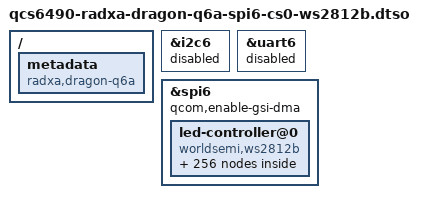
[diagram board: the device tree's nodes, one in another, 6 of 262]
// SPDX-License-Identifier: BSD-3-Clause
/*
 * Copyright (c) 2025 Radxa Computer (Shenzhen) Co., Ltd.
 */

/dts-v1/;
/plugin/;

#include <dt-bindings/leds/common.h>

/ {
    metadata {
        title = "Enable WS2812B on SPI6 over CS0";
        compatible = "radxa,dragon-q6a", "radxa,cm-q64-rpi-cm5-io";
        category = "misc";
        exclusive = "spi6", "uart6", "i2c6", "gpio24", "gpio25", "gpio26", "gpio27";
        description = "Enable WS2812B on SPI6 over CS0.
On Radxa Dragon Q6A and
Radxa CM-Q64 Raspberry Pi Compute Module 5 IO Board,
this is pin 3(miso), 5(mosi), 16(sclk), 18(cs0).";
    };
};

&i2c6 {
	status = "disabled";
};

&uart6 {
	status = "disabled";
};

&spi6 {
	qcom,enable-gsi-dma;
	status = "okay";
	
	led-controller@0 {
		compatible = "worldsemi,ws2812b";
		reg = <0>;
		#address-cells = <1>;
		#size-cells = <0>;
		spi-max-frequency = <2850000>;

		multi-led@0 {
			reg = <0>;
			color-index = <LED_COLOR_ID_RED LED_COLOR_ID_GREEN LED_COLOR_ID_BLUE>;
			color = <LED_COLOR_ID_RGB>;
			function = LED_FUNCTION_STATUS;
			function-enumerator = <0>;
		};

		multi-led@1 {
			reg = <1>;
			color = <LED_COLOR_ID_RGB>;
			function = LED_FUNCTION_STATUS;
			function-enumerator = <1>;
		};

		multi-led@2 {
			reg = <2>;
			color = <LED_COLOR_ID_RGB>;
			function = LED_FUNCTION_STATUS;
			function-enumerator = <2>;
		};

		multi-led@3 {
			reg = <3>;
			color = <LED_COLOR_ID_RGB>;
			function = LED_FUNCTION_STATUS;
			function-enumerator = <3>;
		};

		multi-led@4 {
			reg = <4>;
			color = <LED_COLOR_ID_RGB>;
			function = LED_FUNCTION_STATUS;
			function-enumerator = <4>;
		};

		multi-led@5 {
			reg = <5>;
			color = <LED_COLOR_ID_RGB>;
			function = LED_FUNCTION_STATUS;
			function-enumerator = <5>;
		};

		multi-led@6 {
			reg = <6>;
			color = <LED_COLOR_ID_RGB>;
			function = LED_FUNCTION_STATUS;
			function-enumerator = <6>;
		};

		multi-led@7 {
			reg = <7>;
			color = <LED_COLOR_ID_RGB>;
			function = LED_FUNCTION_STATUS;
			function-enumerator = <7>;
		};

		multi-led@8 {
			reg = <8>;
			color = <LED_COLOR_ID_RGB>;
			function = LED_FUNCTION_STATUS;
			function-enumerator = <8>;
		};

		multi-led@9 {
			reg = <9>;
			color = <LED_COLOR_ID_RGB>;
			function = LED_FUNCTION_STATUS;
			function-enumerator = <9>;
		};

		multi-led@10 {
			reg = <10>;
			color = <LED_COLOR_ID_RGB>;
			function = LED_FUNCTION_STATUS;
			function-enumerator = <10>;
		};

		multi-led@11 {
			reg = <11>;
			color = <LED_COLOR_ID_RGB>;
			function = LED_FUNCTION_STATUS;
			function-enumerator = <11>;
		};

		multi-led@12 {
			reg = <12>;
			color = <LED_COLOR_ID_RGB>;
			function = LED_FUNCTION_STATUS;
			function-enumerator = <12>;
		};

		multi-led@13 {
			reg = <13>;
			color = <LED_COLOR_ID_RGB>;
			function = LED_FUNCTION_STATUS;
			function-enumerator = <13>;
		};

		multi-led@14 {
			reg = <14>;
			color = <LED_COLOR_ID_RGB>;
			function = LED_FUNCTION_STATUS;
			function-enumerator = <14>;
		};

		multi-led@15 {
			reg = <15>;
			color = <LED_COLOR_ID_RGB>;
			function = LED_FUNCTION_STATUS;
			function-enumerator = <15>;
		};

		multi-led@16 {
			reg = <16>;
			color = <LED_COLOR_ID_RGB>;
			function = LED_FUNCTION_STATUS;
			function-enumerator = <16>;
		};

		multi-led@17 {
			reg = <17>;
			color = <LED_COLOR_ID_RGB>;
			function = LED_FUNCTION_STATUS;
			function-enumerator = <17>;
		};

		multi-led@18 {
			reg = <18>;
			color = <LED_COLOR_ID_RGB>;
			function = LED_FUNCTION_STATUS;
			function-enumerator = <18>;
		};

		multi-led@19 {
			reg = <19>;
			color = <LED_COLOR_ID_RGB>;
			function = LED_FUNCTION_STATUS;
			function-enumerator = <19>;
		};

		multi-led@20 {
			reg = <20>;
			color = <LED_COLOR_ID_RGB>;
			function = LED_FUNCTION_STATUS;
			function-enumerator = <20>;
		};

		multi-led@21 {
			reg = <21>;
			color = <LED_COLOR_ID_RGB>;
			function = LED_FUNCTION_STATUS;
			function-enumerator = <21>;
		};

		multi-led@22 {
			reg = <22>;
			color = <LED_COLOR_ID_RGB>;
			function = LED_FUNCTION_STATUS;
			function-enumerator = <22>;
		};

		multi-led@23 {
			reg = <23>;
			color = <LED_COLOR_ID_RGB>;
			function = LED_FUNCTION_STATUS;
			function-enumerator = <23>;
		};

		multi-led@24 {
			reg = <24>;
			color = <LED_COLOR_ID_RGB>;
			function = LED_FUNCTION_STATUS;
			function-enumerator = <24>;
		};

		multi-led@25 {
			reg = <25>;
			color = <LED_COLOR_ID_RGB>;
			function = LED_FUNCTION_STATUS;
			function-enumerator = <25>;
		};

		multi-led@26 {
			reg = <26>;
			color = <LED_COLOR_ID_RGB>;
			function = LED_FUNCTION_STATUS;
			function-enumerator = <26>;
		};

		multi-led@27 {
			reg = <27>;
			color = <LED_COLOR_ID_RGB>;
			function = LED_FUNCTION_STATUS;
			function-enumerator = <27>;
		};

		multi-led@28 {
			reg = <28>;
			color = <LED_COLOR_ID_RGB>;
			function = LED_FUNCTION_STATUS;
			function-enumerator = <28>;
		};

		multi-led@29 {
			reg = <29>;
			color = <LED_COLOR_ID_RGB>;
			function = LED_FUNCTION_STATUS;
			function-enumerator = <29>;
		};

		multi-led@30 {
			reg = <30>;
			color = <LED_COLOR_ID_RGB>;
			function = LED_FUNCTION_STATUS;
			function-enumerator = <30>;
		};

		multi-led@31 {
			reg = <31>;
			color = <LED_COLOR_ID_RGB>;
			function = LED_FUNCTION_STATUS;
			function-enumerator = <31>;
		};

		multi-led@32 {
			reg = <32>;
			color = <LED_COLOR_ID_RGB>;
			function = LED_FUNCTION_STATUS;
			function-enumerator = <32>;
		};

		multi-led@33 {
			reg = <33>;
			color = <LED_COLOR_ID_RGB>;
			function = LED_FUNCTION_STATUS;
			function-enumerator = <33>;
		};

		multi-led@34 {
			reg = <34>;
			color = <LED_COLOR_ID_RGB>;
			function = LED_FUNCTION_STATUS;
			function-enumerator = <34>;
		};

		multi-led@35 {
			reg = <35>;
			color = <LED_COLOR_ID_RGB>;
			function = LED_FUNCTION_STATUS;
			function-enumerator = <35>;
		};

		multi-led@36 {
			reg = <36>;
			color = <LED_COLOR_ID_RGB>;
			function = LED_FUNCTION_STATUS;
			function-enumerator = <36>;
		};

		multi-led@37 {
			reg = <37>;
			color = <LED_COLOR_ID_RGB>;
			function = LED_FUNCTION_STATUS;
			function-enumerator = <37>;
		};

		multi-led@38 {
			reg = <38>;
			color = <LED_COLOR_ID_RGB>;
			function = LED_FUNCTION_STATUS;
			function-enumerator = <38>;
		};

		multi-led@39 {
			reg = <39>;
			color = <LED_COLOR_ID_RGB>;
			function = LED_FUNCTION_STATUS;
			function-enumerator = <39>;
		};

		multi-led@40 {
			reg = <40>;
			color = <LED_COLOR_ID_RGB>;
			function = LED_FUNCTION_STATUS;
			function-enumerator = <40>;
		};

		multi-led@41 {
			reg = <41>;
			color = <LED_COLOR_ID_RGB>;
			function = LED_FUNCTION_STATUS;
			function-enumerator = <41>;
		};

		multi-led@42 {
			reg = <42>;
			color = <LED_COLOR_ID_RGB>;
			function = LED_FUNCTION_STATUS;
			function-enumerator = <42>;
		};

		multi-led@43 {
			reg = <43>;
			color = <LED_COLOR_ID_RGB>;
			function = LED_FUNCTION_STATUS;
			function-enumerator = <43>;
		};

		multi-led@44 {
			reg = <44>;
			color = <LED_COLOR_ID_RGB>;
			function = LED_FUNCTION_STATUS;
			function-enumerator = <44>;
		};

		multi-led@45 {
			reg = <45>;
			color = <LED_COLOR_ID_RGB>;
			function = LED_FUNCTION_STATUS;
			function-enumerator = <45>;
		};

		multi-led@46 {
			reg = <46>;
			color = <LED_COLOR_ID_RGB>;
			function = LED_FUNCTION_STATUS;
			function-enumerator = <46>;
		};

		multi-led@47 {
			reg = <47>;
			color = <LED_COLOR_ID_RGB>;
			function = LED_FUNCTION_STATUS;
			function-enumerator = <47>;
		};

		multi-led@48 {
			reg = <48>;
			color = <LED_COLOR_ID_RGB>;
			function = LED_FUNCTION_STATUS;
			function-enumerator = <48>;
		};

		multi-led@49 {
			reg = <49>;
			color = <LED_COLOR_ID_RGB>;
			function = LED_FUNCTION_STATUS;
			function-enumerator = <49>;
		};

		multi-led@50 {
			reg = <50>;
			color = <LED_COLOR_ID_RGB>;
			function = LED_FUNCTION_STATUS;
			function-enumerator = <50>;
		};

		multi-led@51 {
			reg = <51>;
			color = <LED_COLOR_ID_RGB>;
			function = LED_FUNCTION_STATUS;
			function-enumerator = <51>;
		};

		multi-led@52 {
			reg = <52>;
			color = <LED_COLOR_ID_RGB>;
			function = LED_FUNCTION_STATUS;
			function-enumerator = <52>;
		};

		multi-led@53 {
			reg = <53>;
			color = <LED_COLOR_ID_RGB>;
			function = LED_FUNCTION_STATUS;
			function-enumerator = <53>;
		};

		multi-led@54 {
			reg = <54>;
			color = <LED_COLOR_ID_RGB>;
			function = LED_FUNCTION_STATUS;
			function-enumerator = <54>;
		};

		multi-led@55 {
			reg = <55>;
			color = <LED_COLOR_ID_RGB>;
			function = LED_FUNCTION_STATUS;
			function-enumerator = <55>;
		};

		multi-led@56 {
			reg = <56>;
			color = <LED_COLOR_ID_RGB>;
			function = LED_FUNCTION_STATUS;
			function-enumerator = <56>;
		};

		multi-led@57 {
			reg = <57>;
			color = <LED_COLOR_ID_RGB>;
			function = LED_FUNCTION_STATUS;
			function-enumerator = <57>;
		};

		multi-led@58 {
			reg = <58>;
			color = <LED_COLOR_ID_RGB>;
			function = LED_FUNCTION_STATUS;
			function-enumerator = <58>;
		};

		multi-led@59 {
			reg = <59>;
			color = <LED_COLOR_ID_RGB>;
			function = LED_FUNCTION_STATUS;
			function-enumerator = <59>;
		};

		multi-led@60 {
			reg = <60>;
			color = <LED_COLOR_ID_RGB>;
			function = LED_FUNCTION_STATUS;
			function-enumerator = <60>;
		};

		multi-led@61 {
			reg = <61>;
			color = <LED_COLOR_ID_RGB>;
			function = LED_FUNCTION_STATUS;
			function-enumerator = <61>;
		};

		multi-led@62 {
			reg = <62>;
			color = <LED_COLOR_ID_RGB>;
			function = LED_FUNCTION_STATUS;
			function-enumerator = <62>;
		};

		multi-led@63 {
			reg = <63>;
			color = <LED_COLOR_ID_RGB>;
			function = LED_FUNCTION_STATUS;
			function-enumerator = <63>;
		};

		multi-led@64 {
			reg = <64>;
			color = <LED_COLOR_ID_RGB>;
			function = LED_FUNCTION_STATUS;
			function-enumerator = <64>;
		};

		multi-led@65 {
			reg = <65>;
			color = <LED_COLOR_ID_RGB>;
			function = LED_FUNCTION_STATUS;
			function-enumerator = <65>;
		};

		multi-led@66 {
			reg = <66>;
			color = <LED_COLOR_ID_RGB>;
			function = LED_FUNCTION_STATUS;
			function-enumerator = <66>;
		};

		multi-led@67 {
			reg = <67>;
			color = <LED_COLOR_ID_RGB>;
			function = LED_FUNCTION_STATUS;
			function-enumerator = <67>;
		};

		multi-led@68 {
			reg = <68>;
			color = <LED_COLOR_ID_RGB>;
			function = LED_FUNCTION_STATUS;
			function-enumerator = <68>;
		};

		multi-led@69 {
			reg = <69>;
			color = <LED_COLOR_ID_RGB>;
			function = LED_FUNCTION_STATUS;
			function-enumerator = <69>;
		};

		multi-led@70 {
			reg = <70>;
			color = <LED_COLOR_ID_RGB>;
			function = LED_FUNCTION_STATUS;
			function-enumerator = <70>;
		};

		multi-led@71 {
			reg = <71>;
			color = <LED_COLOR_ID_RGB>;
			function = LED_FUNCTION_STATUS;
			function-enumerator = <71>;
		};

		multi-led@72 {
			reg = <72>;
			color = <LED_COLOR_ID_RGB>;
			function = LED_FUNCTION_STATUS;
			function-enumerator = <72>;
		};

		multi-led@73 {
			reg = <73>;
			color = <LED_COLOR_ID_RGB>;
			function = LED_FUNCTION_STATUS;
			function-enumerator = <73>;
		};

		multi-led@74 {
			reg = <74>;
			color = <LED_COLOR_ID_RGB>;
			function = LED_FUNCTION_STATUS;
			function-enumerator = <74>;
		};

		multi-led@75 {
			reg = <75>;
			color = <LED_COLOR_ID_RGB>;
			function = LED_FUNCTION_STATUS;
			function-enumerator = <75>;
		};

		multi-led@76 {
			reg = <76>;
			color = <LED_COLOR_ID_RGB>;
			function = LED_FUNCTION_STATUS;
			function-enumerator = <76>;
		};

		multi-led@77 {
			reg = <77>;
			color = <LED_COLOR_ID_RGB>;
			function = LED_FUNCTION_STATUS;
			function-enumerator = <77>;
		};

		multi-led@78 {
			reg = <78>;
			color = <LED_COLOR_ID_RGB>;
			function = LED_FUNCTION_STATUS;
			function-enumerator = <78>;
		};

		multi-led@79 {
			reg = <79>;
			color = <LED_COLOR_ID_RGB>;
			function = LED_FUNCTION_STATUS;
			function-enumerator = <79>;
		};

		multi-led@80 {
			reg = <80>;
			color = <LED_COLOR_ID_RGB>;
			function = LED_FUNCTION_STATUS;
			function-enumerator = <80>;
		};

		multi-led@81 {
			reg = <81>;
			color = <LED_COLOR_ID_RGB>;
			function = LED_FUNCTION_STATUS;
			function-enumerator = <81>;
		};

		multi-led@82 {
			reg = <82>;
			color = <LED_COLOR_ID_RGB>;
			function = LED_FUNCTION_STATUS;
			function-enumerator = <82>;
		};

		multi-led@83 {
			reg = <83>;
			color = <LED_COLOR_ID_RGB>;
			function = LED_FUNCTION_STATUS;
			function-enumerator = <83>;
		};

		multi-led@84 {
			reg = <84>;
			color = <LED_COLOR_ID_RGB>;
			function = LED_FUNCTION_STATUS;
			function-enumerator = <84>;
		};

		multi-led@85 {
			reg = <85>;
			color = <LED_COLOR_ID_RGB>;
			function = LED_FUNCTION_STATUS;
			function-enumerator = <85>;
		};

		multi-led@86 {
			reg = <86>;
			color = <LED_COLOR_ID_RGB>;
			function = LED_FUNCTION_STATUS;
			function-enumerator = <86>;
		};

		multi-led@87 {
			reg = <87>;
			color = <LED_COLOR_ID_RGB>;
			function = LED_FUNCTION_STATUS;
			function-enumerator = <87>;
		};

		multi-led@88 {
			reg = <88>;
			color = <LED_COLOR_ID_RGB>;
			function = LED_FUNCTION_STATUS;
			function-enumerator = <88>;
		};

		multi-led@89 {
			reg = <89>;
			color = <LED_COLOR_ID_RGB>;
			function = LED_FUNCTION_STATUS;
			function-enumerator = <89>;
		};

		multi-led@90 {
			reg = <90>;
			color = <LED_COLOR_ID_RGB>;
			function = LED_FUNCTION_STATUS;
			function-enumerator = <90>;
		};

		multi-led@91 {
			reg = <91>;
			color = <LED_COLOR_ID_RGB>;
			function = LED_FUNCTION_STATUS;
			function-enumerator = <91>;
		};

		multi-led@92 {
			reg = <92>;
			color = <LED_COLOR_ID_RGB>;
			function = LED_FUNCTION_STATUS;
			function-enumerator = <92>;
		};

		multi-led@93 {
			reg = <93>;
			color = <LED_COLOR_ID_RGB>;
			function = LED_FUNCTION_STATUS;
			function-enumerator = <93>;
		};

		multi-led@94 {
			reg = <94>;
			color = <LED_COLOR_ID_RGB>;
			function = LED_FUNCTION_STATUS;
			function-enumerator = <94>;
		};

		multi-led@95 {
			reg = <95>;
			color = <LED_COLOR_ID_RGB>;
			function = LED_FUNCTION_STATUS;
			function-enumerator = <95>;
		};

		multi-led@96 {
			reg = <96>;
			color = <LED_COLOR_ID_RGB>;
			function = LED_FUNCTION_STATUS;
			function-enumerator = <96>;
		};

		multi-led@97 {
			reg = <97>;
			color = <LED_COLOR_ID_RGB>;
			function = LED_FUNCTION_STATUS;
			function-enumerator = <97>;
		};

		multi-led@98 {
			reg = <98>;
			color = <LED_COLOR_ID_RGB>;
			function = LED_FUNCTION_STATUS;
			function-enumerator = <98>;
		};

		multi-led@99 {
			reg = <99>;
			color = <LED_COLOR_ID_RGB>;
			function = LED_FUNCTION_STATUS;
			function-enumerator = <99>;
		};

		multi-led@100 {
			reg = <100>;
			color = <LED_COLOR_ID_RGB>;
			function = LED_FUNCTION_STATUS;
			function-enumerator = <100>;
		};

		multi-led@101 {
			reg = <101>;
			color = <LED_COLOR_ID_RGB>;
			function = LED_FUNCTION_STATUS;
			function-enumerator = <101>;
		};

		multi-led@102 {
			reg = <102>;
			color = <LED_COLOR_ID_RGB>;
			function = LED_FUNCTION_STATUS;
			function-enumerator = <102>;
		};

		multi-led@103 {
			reg = <103>;
			color = <LED_COLOR_ID_RGB>;
			function = LED_FUNCTION_STATUS;
			function-enumerator = <103>;
		};

		multi-led@104 {
			reg = <104>;
			color = <LED_COLOR_ID_RGB>;
			function = LED_FUNCTION_STATUS;
			function-enumerator = <104>;
		};

		multi-led@105 {
			reg = <105>;
			color = <LED_COLOR_ID_RGB>;
			function = LED_FUNCTION_STATUS;
			function-enumerator = <105>;
		};

		multi-led@106 {
			reg = <106>;
			color = <LED_COLOR_ID_RGB>;
			function = LED_FUNCTION_STATUS;
			function-enumerator = <106>;
		};

		multi-led@107 {
			reg = <107>;
			color = <LED_COLOR_ID_RGB>;
			function = LED_FUNCTION_STATUS;
			function-enumerator = <107>;
		};

		multi-led@108 {
			reg = <108>;
			color = <LED_COLOR_ID_RGB>;
			function = LED_FUNCTION_STATUS;
			function-enumerator = <108>;
		};

		multi-led@109 {
			reg = <109>;
			color = <LED_COLOR_ID_RGB>;
			function = LED_FUNCTION_STATUS;
			function-enumerator = <109>;
		};

		multi-led@110 {
			reg = <110>;
			color = <LED_COLOR_ID_RGB>;
			function = LED_FUNCTION_STATUS;
			function-enumerator = <110>;
		};

		multi-led@111 {
			reg = <111>;
			color = <LED_COLOR_ID_RGB>;
			function = LED_FUNCTION_STATUS;
			function-enumerator = <111>;
		};

		multi-led@112 {
			reg = <112>;
			color = <LED_COLOR_ID_RGB>;
			function = LED_FUNCTION_STATUS;
			function-enumerator = <112>;
		};

		multi-led@113 {
			reg = <113>;
			color = <LED_COLOR_ID_RGB>;
			function = LED_FUNCTION_STATUS;
			function-enumerator = <113>;
		};

		multi-led@114 {
			reg = <114>;
			color = <LED_COLOR_ID_RGB>;
			function = LED_FUNCTION_STATUS;
			function-enumerator = <114>;
		};

		multi-led@115 {
			reg = <115>;
			color = <LED_COLOR_ID_RGB>;
			function = LED_FUNCTION_STATUS;
			function-enumerator = <115>;
		};

		multi-led@116 {
			reg = <116>;
			color = <LED_COLOR_ID_RGB>;
			function = LED_FUNCTION_STATUS;
			function-enumerator = <116>;
		};

		multi-led@117 {
			reg = <117>;
			color = <LED_COLOR_ID_RGB>;
			function = LED_FUNCTION_STATUS;
			function-enumerator = <117>;
		};

		multi-led@118 {
			reg = <118>;
			color = <LED_COLOR_ID_RGB>;
			function = LED_FUNCTION_STATUS;
			function-enumerator = <118>;
		};

		multi-led@119 {
			reg = <119>;
			color = <LED_COLOR_ID_RGB>;
			function = LED_FUNCTION_STATUS;
			function-enumerator = <119>;
		};

		multi-led@120 {
			reg = <120>;
			color = <LED_COLOR_ID_RGB>;
			function = LED_FUNCTION_STATUS;
			function-enumerator = <120>;
		};

		multi-led@121 {
			reg = <121>;
			color = <LED_COLOR_ID_RGB>;
			function = LED_FUNCTION_STATUS;
			function-enumerator = <121>;
		};

		multi-led@122 {
			reg = <122>;
			color = <LED_COLOR_ID_RGB>;
			function = LED_FUNCTION_STATUS;
			function-enumerator = <122>;
		};

		multi-led@123 {
			reg = <123>;
			color = <LED_COLOR_ID_RGB>;
			function = LED_FUNCTION_STATUS;
			function-enumerator = <123>;
		};

		multi-led@124 {
			reg = <124>;
			color = <LED_COLOR_ID_RGB>;
			function = LED_FUNCTION_STATUS;
			function-enumerator = <124>;
		};

		multi-led@125 {
			reg = <125>;
			color = <LED_COLOR_ID_RGB>;
			function = LED_FUNCTION_STATUS;
			function-enumerator = <125>;
		};

		multi-led@126 {
			reg = <126>;
			color = <LED_COLOR_ID_RGB>;
			function = LED_FUNCTION_STATUS;
			function-enumerator = <126>;
		};

		multi-led@127 {
			reg = <127>;
			color = <LED_COLOR_ID_RGB>;
			function = LED_FUNCTION_STATUS;
			function-enumerator = <127>;
		};

		multi-led@128 {
			reg = <128>;
			color = <LED_COLOR_ID_RGB>;
			function = LED_FUNCTION_STATUS;
			function-enumerator = <128>;
		};

		multi-led@129 {
			reg = <129>;
			color = <LED_COLOR_ID_RGB>;
			function = LED_FUNCTION_STATUS;
			function-enumerator = <129>;
		};

		multi-led@130 {
			reg = <130>;
			color = <LED_COLOR_ID_RGB>;
			function = LED_FUNCTION_STATUS;
			function-enumerator = <130>;
		};

		multi-led@131 {
			reg = <131>;
			color = <LED_COLOR_ID_RGB>;
			function = LED_FUNCTION_STATUS;
			function-enumerator = <131>;
		};

		multi-led@132 {
			reg = <132>;
			color = <LED_COLOR_ID_RGB>;
			function = LED_FUNCTION_STATUS;
			function-enumerator = <132>;
		};

		multi-led@133 {
			reg = <133>;
			color = <LED_COLOR_ID_RGB>;
			function = LED_FUNCTION_STATUS;
			function-enumerator = <133>;
		};

		multi-led@134 {
			reg = <134>;
			color = <LED_COLOR_ID_RGB>;
			function = LED_FUNCTION_STATUS;
			function-enumerator = <134>;
		};

		multi-led@135 {
			reg = <135>;
			color = <LED_COLOR_ID_RGB>;
			function = LED_FUNCTION_STATUS;
			function-enumerator = <135>;
		};

		multi-led@136 {
			reg = <136>;
			color = <LED_COLOR_ID_RGB>;
			function = LED_FUNCTION_STATUS;
			function-enumerator = <136>;
		};

		multi-led@137 {
			reg = <137>;
			color = <LED_COLOR_ID_RGB>;
			function = LED_FUNCTION_STATUS;
			function-enumerator = <137>;
		};

		multi-led@138 {
			reg = <138>;
			color = <LED_COLOR_ID_RGB>;
			function = LED_FUNCTION_STATUS;
			function-enumerator = <138>;
		};

		multi-led@139 {
			reg = <139>;
			color = <LED_COLOR_ID_RGB>;
			function = LED_FUNCTION_STATUS;
			function-enumerator = <139>;
		};

		multi-led@140 {
			reg = <140>;
			color = <LED_COLOR_ID_RGB>;
			function = LED_FUNCTION_STATUS;
			function-enumerator = <140>;
		};

		multi-led@141 {
			reg = <141>;
			color = <LED_COLOR_ID_RGB>;
			function = LED_FUNCTION_STATUS;
			function-enumerator = <141>;
		};

		multi-led@142 {
			reg = <142>;
			color = <LED_COLOR_ID_RGB>;
			function = LED_FUNCTION_STATUS;
			function-enumerator = <142>;
		};

		multi-led@143 {
			reg = <143>;
			color = <LED_COLOR_ID_RGB>;
			function = LED_FUNCTION_STATUS;
			function-enumerator = <143>;
		};

		multi-led@144 {
			reg = <144>;
			color = <LED_COLOR_ID_RGB>;
			function = LED_FUNCTION_STATUS;
			function-enumerator = <144>;
		};

		multi-led@145 {
			reg = <145>;
			color = <LED_COLOR_ID_RGB>;
			function = LED_FUNCTION_STATUS;
			function-enumerator = <145>;
		};

		multi-led@146 {
			reg = <146>;
			color = <LED_COLOR_ID_RGB>;
			function = LED_FUNCTION_STATUS;
			function-enumerator = <146>;
		};

		multi-led@147 {
			reg = <147>;
			color = <LED_COLOR_ID_RGB>;
			function = LED_FUNCTION_STATUS;
			function-enumerator = <147>;
		};

		multi-led@148 {
			reg = <148>;
			color = <LED_COLOR_ID_RGB>;
			function = LED_FUNCTION_STATUS;
			function-enumerator = <148>;
		};

		multi-led@149 {
			reg = <149>;
			color = <LED_COLOR_ID_RGB>;
			function = LED_FUNCTION_STATUS;
			function-enumerator = <149>;
		};

		multi-led@150 {
			reg = <150>;
			color = <LED_COLOR_ID_RGB>;
			function = LED_FUNCTION_STATUS;
			function-enumerator = <150>;
		};

		multi-led@151 {
			reg = <151>;
			color = <LED_COLOR_ID_RGB>;
			function = LED_FUNCTION_STATUS;
			function-enumerator = <151>;
		};

		multi-led@152 {
			reg = <152>;
			color = <LED_COLOR_ID_RGB>;
			function = LED_FUNCTION_STATUS;
			function-enumerator = <152>;
		};

		multi-led@153 {
			reg = <153>;
			color = <LED_COLOR_ID_RGB>;
			function = LED_FUNCTION_STATUS;
			function-enumerator = <153>;
		};

		multi-led@154 {
			reg = <154>;
			color = <LED_COLOR_ID_RGB>;
			function = LED_FUNCTION_STATUS;
			function-enumerator = <154>;
		};

		multi-led@155 {
			reg = <155>;
			color = <LED_COLOR_ID_RGB>;
			function = LED_FUNCTION_STATUS;
			function-enumerator = <155>;
		};

		multi-led@156 {
			reg = <156>;
			color = <LED_COLOR_ID_RGB>;
			function = LED_FUNCTION_STATUS;
			function-enumerator = <156>;
		};

		multi-led@157 {
			reg = <157>;
			color = <LED_COLOR_ID_RGB>;
			function = LED_FUNCTION_STATUS;
			function-enumerator = <157>;
		};

		multi-led@158 {
			reg = <158>;
			color = <LED_COLOR_ID_RGB>;
			function = LED_FUNCTION_STATUS;
			function-enumerator = <158>;
		};

		multi-led@159 {
			reg = <159>;
			color = <LED_COLOR_ID_RGB>;
			function = LED_FUNCTION_STATUS;
			function-enumerator = <159>;
		};

		multi-led@160 {
			reg = <160>;
			color = <LED_COLOR_ID_RGB>;
			function = LED_FUNCTION_STATUS;
			function-enumerator = <160>;
		};

		multi-led@161 {
			reg = <161>;
			color = <LED_COLOR_ID_RGB>;
			function = LED_FUNCTION_STATUS;
			function-enumerator = <161>;
		};

		multi-led@162 {
			reg = <162>;
			color = <LED_COLOR_ID_RGB>;
			function = LED_FUNCTION_STATUS;
			function-enumerator = <162>;
		};

		multi-led@163 {
			reg = <163>;
			color = <LED_COLOR_ID_RGB>;
			function = LED_FUNCTION_STATUS;
			function-enumerator = <163>;
		};

		multi-led@164 {
			reg = <164>;
			color = <LED_COLOR_ID_RGB>;
			function = LED_FUNCTION_STATUS;
			function-enumerator = <164>;
		};

		multi-led@165 {
			reg = <165>;
			color = <LED_COLOR_ID_RGB>;
			function = LED_FUNCTION_STATUS;
			function-enumerator = <165>;
		};

		multi-led@166 {
			reg = <166>;
			color = <LED_COLOR_ID_RGB>;
			function = LED_FUNCTION_STATUS;
			function-enumerator = <166>;
		};

		multi-led@167 {
			reg = <167>;
			color = <LED_COLOR_ID_RGB>;
			function = LED_FUNCTION_STATUS;
			function-enumerator = <167>;
		};

		multi-led@168 {
			reg = <168>;
			color = <LED_COLOR_ID_RGB>;
			function = LED_FUNCTION_STATUS;
			function-enumerator = <168>;
		};

		multi-led@169 {
			reg = <169>;
			color = <LED_COLOR_ID_RGB>;
			function = LED_FUNCTION_STATUS;
			function-enumerator = <169>;
		};

		multi-led@170 {
			reg = <170>;
			color = <LED_COLOR_ID_RGB>;
			function = LED_FUNCTION_STATUS;
			function-enumerator = <170>;
		};

		multi-led@171 {
			reg = <171>;
			color = <LED_COLOR_ID_RGB>;
			function = LED_FUNCTION_STATUS;
			function-enumerator = <171>;
		};

		multi-led@172 {
			reg = <172>;
			color = <LED_COLOR_ID_RGB>;
			function = LED_FUNCTION_STATUS;
			function-enumerator = <172>;
		};

		multi-led@173 {
			reg = <173>;
			color = <LED_COLOR_ID_RGB>;
			function = LED_FUNCTION_STATUS;
			function-enumerator = <173>;
		};

		multi-led@174 {
			reg = <174>;
			color = <LED_COLOR_ID_RGB>;
			function = LED_FUNCTION_STATUS;
			function-enumerator = <174>;
		};

		multi-led@175 {
			reg = <175>;
			color = <LED_COLOR_ID_RGB>;
			function = LED_FUNCTION_STATUS;
			function-enumerator = <175>;
		};

		multi-led@176 {
			reg = <176>;
			color = <LED_COLOR_ID_RGB>;
			function = LED_FUNCTION_STATUS;
			function-enumerator = <176>;
		};

		multi-led@177 {
			reg = <177>;
			color = <LED_COLOR_ID_RGB>;
			function = LED_FUNCTION_STATUS;
			function-enumerator = <177>;
		};

		multi-led@178 {
			reg = <178>;
			color = <LED_COLOR_ID_RGB>;
			function = LED_FUNCTION_STATUS;
			function-enumerator = <178>;
		};

		multi-led@179 {
			reg = <179>;
			color = <LED_COLOR_ID_RGB>;
			function = LED_FUNCTION_STATUS;
			function-enumerator = <179>;
		};

		multi-led@180 {
			reg = <180>;
			color = <LED_COLOR_ID_RGB>;
			function = LED_FUNCTION_STATUS;
			function-enumerator = <180>;
		};

		multi-led@181 {
			reg = <181>;
			color = <LED_COLOR_ID_RGB>;
			function = LED_FUNCTION_STATUS;
			function-enumerator = <181>;
		};

		multi-led@182 {
			reg = <182>;
			color = <LED_COLOR_ID_RGB>;
			function = LED_FUNCTION_STATUS;
			function-enumerator = <182>;
		};

		multi-led@183 {
			reg = <183>;
			color = <LED_COLOR_ID_RGB>;
			function = LED_FUNCTION_STATUS;
			function-enumerator = <183>;
		};

		multi-led@184 {
			reg = <184>;
			color = <LED_COLOR_ID_RGB>;
			function = LED_FUNCTION_STATUS;
			function-enumerator = <184>;
		};

		multi-led@185 {
			reg = <185>;
			color = <LED_COLOR_ID_RGB>;
			function = LED_FUNCTION_STATUS;
			function-enumerator = <185>;
		};

		multi-led@186 {
			reg = <186>;
			color = <LED_COLOR_ID_RGB>;
			function = LED_FUNCTION_STATUS;
			function-enumerator = <186>;
		};

		multi-led@187 {
			reg = <187>;
			color = <LED_COLOR_ID_RGB>;
			function = LED_FUNCTION_STATUS;
			function-enumerator = <187>;
		};

		multi-led@188 {
			reg = <188>;
			color = <LED_COLOR_ID_RGB>;
			function = LED_FUNCTION_STATUS;
			function-enumerator = <188>;
		};

		multi-led@189 {
			reg = <189>;
			color = <LED_COLOR_ID_RGB>;
			function = LED_FUNCTION_STATUS;
			function-enumerator = <189>;
		};

		multi-led@190 {
			reg = <190>;
			color = <LED_COLOR_ID_RGB>;
			function = LED_FUNCTION_STATUS;
			function-enumerator = <190>;
		};

		multi-led@191 {
			reg = <191>;
			color = <LED_COLOR_ID_RGB>;
			function = LED_FUNCTION_STATUS;
			function-enumerator = <191>;
		};

		multi-led@192 {
			reg = <192>;
			color = <LED_COLOR_ID_RGB>;
			function = LED_FUNCTION_STATUS;
			function-enumerator = <192>;
		};

		multi-led@193 {
			reg = <193>;
			color = <LED_COLOR_ID_RGB>;
			function = LED_FUNCTION_STATUS;
			function-enumerator = <193>;
		};

		multi-led@194 {
			reg = <194>;
			color = <LED_COLOR_ID_RGB>;
			function = LED_FUNCTION_STATUS;
			function-enumerator = <194>;
		};

		multi-led@195 {
			reg = <195>;
			color = <LED_COLOR_ID_RGB>;
			function = LED_FUNCTION_STATUS;
			function-enumerator = <195>;
		};

		multi-led@196 {
			reg = <196>;
			color = <LED_COLOR_ID_RGB>;
			function = LED_FUNCTION_STATUS;
			function-enumerator = <196>;
		};

		multi-led@197 {
			reg = <197>;
			color = <LED_COLOR_ID_RGB>;
			function = LED_FUNCTION_STATUS;
			function-enumerator = <197>;
		};

		multi-led@198 {
			reg = <198>;
			color = <LED_COLOR_ID_RGB>;
			function = LED_FUNCTION_STATUS;
			function-enumerator = <198>;
		};

		multi-led@199 {
			reg = <199>;
			color = <LED_COLOR_ID_RGB>;
			function = LED_FUNCTION_STATUS;
			function-enumerator = <199>;
		};

		multi-led@200 {
			reg = <200>;
			color = <LED_COLOR_ID_RGB>;
			function = LED_FUNCTION_STATUS;
			function-enumerator = <200>;
		};

		multi-led@201 {
			reg = <201>;
			color = <LED_COLOR_ID_RGB>;
			function = LED_FUNCTION_STATUS;
			function-enumerator = <201>;
		};

		multi-led@202 {
			reg = <202>;
			color = <LED_COLOR_ID_RGB>;
			function = LED_FUNCTION_STATUS;
			function-enumerator = <202>;
		};

		multi-led@203 {
			reg = <203>;
			color = <LED_COLOR_ID_RGB>;
			function = LED_FUNCTION_STATUS;
			function-enumerator = <203>;
		};

		multi-led@204 {
			reg = <204>;
			color = <LED_COLOR_ID_RGB>;
			function = LED_FUNCTION_STATUS;
			function-enumerator = <204>;
		};

		multi-led@205 {
			reg = <205>;
			color = <LED_COLOR_ID_RGB>;
			function = LED_FUNCTION_STATUS;
			function-enumerator = <205>;
		};

		multi-led@206 {
			reg = <206>;
			color = <LED_COLOR_ID_RGB>;
			function = LED_FUNCTION_STATUS;
			function-enumerator = <206>;
		};

		multi-led@207 {
			reg = <207>;
			color = <LED_COLOR_ID_RGB>;
			function = LED_FUNCTION_STATUS;
			function-enumerator = <207>;
		};

		multi-led@208 {
			reg = <208>;
			color = <LED_COLOR_ID_RGB>;
			function = LED_FUNCTION_STATUS;
			function-enumerator = <208>;
		};

		multi-led@209 {
			reg = <209>;
			color = <LED_COLOR_ID_RGB>;
			function = LED_FUNCTION_STATUS;
			function-enumerator = <209>;
		};

		multi-led@210 {
			reg = <210>;
			color = <LED_COLOR_ID_RGB>;
			function = LED_FUNCTION_STATUS;
			function-enumerator = <210>;
		};

		multi-led@211 {
			reg = <211>;
			color = <LED_COLOR_ID_RGB>;
			function = LED_FUNCTION_STATUS;
			function-enumerator = <211>;
		};

		multi-led@212 {
			reg = <212>;
			color = <LED_COLOR_ID_RGB>;
			function = LED_FUNCTION_STATUS;
			function-enumerator = <212>;
		};

		multi-led@213 {
			reg = <213>;
			color = <LED_COLOR_ID_RGB>;
			function = LED_FUNCTION_STATUS;
			function-enumerator = <213>;
		};

		multi-led@214 {
			reg = <214>;
			color = <LED_COLOR_ID_RGB>;
			function = LED_FUNCTION_STATUS;
			function-enumerator = <214>;
		};

		multi-led@215 {
			reg = <215>;
			color = <LED_COLOR_ID_RGB>;
			function = LED_FUNCTION_STATUS;
			function-enumerator = <215>;
		};

		multi-led@216 {
			reg = <216>;
			color = <LED_COLOR_ID_RGB>;
			function = LED_FUNCTION_STATUS;
			function-enumerator = <216>;
		};

		multi-led@217 {
			reg = <217>;
			color = <LED_COLOR_ID_RGB>;
			function = LED_FUNCTION_STATUS;
			function-enumerator = <217>;
		};

		multi-led@218 {
			reg = <218>;
			color = <LED_COLOR_ID_RGB>;
			function = LED_FUNCTION_STATUS;
			function-enumerator = <218>;
		};

		multi-led@219 {
			reg = <219>;
			color = <LED_COLOR_ID_RGB>;
			function = LED_FUNCTION_STATUS;
			function-enumerator = <219>;
		};

		multi-led@220 {
			reg = <220>;
			color = <LED_COLOR_ID_RGB>;
			function = LED_FUNCTION_STATUS;
			function-enumerator = <220>;
		};

		multi-led@221 {
			reg = <221>;
			color = <LED_COLOR_ID_RGB>;
			function = LED_FUNCTION_STATUS;
			function-enumerator = <221>;
		};

		multi-led@222 {
			reg = <222>;
			color = <LED_COLOR_ID_RGB>;
			function = LED_FUNCTION_STATUS;
			function-enumerator = <222>;
		};

		multi-led@223 {
			reg = <223>;
			color = <LED_COLOR_ID_RGB>;
			function = LED_FUNCTION_STATUS;
			function-enumerator = <223>;
		};

		multi-led@224 {
			reg = <224>;
			color = <LED_COLOR_ID_RGB>;
			function = LED_FUNCTION_STATUS;
			function-enumerator = <224>;
		};

		multi-led@225 {
			reg = <225>;
			color = <LED_COLOR_ID_RGB>;
			function = LED_FUNCTION_STATUS;
			function-enumerator = <225>;
		};

		multi-led@226 {
			reg = <226>;
			color = <LED_COLOR_ID_RGB>;
			function = LED_FUNCTION_STATUS;
			function-enumerator = <226>;
		};

		multi-led@227 {
			reg = <227>;
			color = <LED_COLOR_ID_RGB>;
			function = LED_FUNCTION_STATUS;
			function-enumerator = <227>;
		};

		multi-led@228 {
			reg = <228>;
			color = <LED_COLOR_ID_RGB>;
			function = LED_FUNCTION_STATUS;
			function-enumerator = <228>;
		};

		multi-led@229 {
			reg = <229>;
			color = <LED_COLOR_ID_RGB>;
			function = LED_FUNCTION_STATUS;
			function-enumerator = <229>;
		};

		multi-led@230 {
			reg = <230>;
			color = <LED_COLOR_ID_RGB>;
			function = LED_FUNCTION_STATUS;
			function-enumerator = <230>;
		};

		multi-led@231 {
			reg = <231>;
			color = <LED_COLOR_ID_RGB>;
			function = LED_FUNCTION_STATUS;
			function-enumerator = <231>;
		};

		multi-led@232 {
			reg = <232>;
			color = <LED_COLOR_ID_RGB>;
			function = LED_FUNCTION_STATUS;
			function-enumerator = <232>;
		};

		multi-led@233 {
			reg = <233>;
			color = <LED_COLOR_ID_RGB>;
			function = LED_FUNCTION_STATUS;
			function-enumerator = <233>;
		};

		multi-led@234 {
			reg = <234>;
			color = <LED_COLOR_ID_RGB>;
			function = LED_FUNCTION_STATUS;
			function-enumerator = <234>;
		};

		multi-led@235 {
			reg = <235>;
			color = <LED_COLOR_ID_RGB>;
			function = LED_FUNCTION_STATUS;
			function-enumerator = <235>;
		};

		multi-led@236 {
			reg = <236>;
			color = <LED_COLOR_ID_RGB>;
			function = LED_FUNCTION_STATUS;
			function-enumerator = <236>;
		};

		multi-led@237 {
			reg = <237>;
			color = <LED_COLOR_ID_RGB>;
			function = LED_FUNCTION_STATUS;
			function-enumerator = <237>;
		};

		multi-led@238 {
			reg = <238>;
			color = <LED_COLOR_ID_RGB>;
			function = LED_FUNCTION_STATUS;
			function-enumerator = <238>;
		};

		multi-led@239 {
			reg = <239>;
			color = <LED_COLOR_ID_RGB>;
			function = LED_FUNCTION_STATUS;
			function-enumerator = <239>;
		};

		multi-led@240 {
			reg = <240>;
			color = <LED_COLOR_ID_RGB>;
			function = LED_FUNCTION_STATUS;
			function-enumerator = <240>;
		};

		multi-led@241 {
			reg = <241>;
			color = <LED_COLOR_ID_RGB>;
			function = LED_FUNCTION_STATUS;
			function-enumerator = <241>;
		};

		multi-led@242 {
			reg = <242>;
			color = <LED_COLOR_ID_RGB>;
			function = LED_FUNCTION_STATUS;
			function-enumerator = <242>;
		};

		multi-led@243 {
			reg = <243>;
			color = <LED_COLOR_ID_RGB>;
			function = LED_FUNCTION_STATUS;
			function-enumerator = <243>;
		};

		multi-led@244 {
			reg = <244>;
			color = <LED_COLOR_ID_RGB>;
			function = LED_FUNCTION_STATUS;
			function-enumerator = <244>;
		};

		multi-led@245 {
			reg = <245>;
			color = <LED_COLOR_ID_RGB>;
			function = LED_FUNCTION_STATUS;
			function-enumerator = <245>;
		};

		multi-led@246 {
			reg = <246>;
			color = <LED_COLOR_ID_RGB>;
			function = LED_FUNCTION_STATUS;
			function-enumerator = <246>;
		};

		multi-led@247 {
			reg = <247>;
			color = <LED_COLOR_ID_RGB>;
			function = LED_FUNCTION_STATUS;
			function-enumerator = <247>;
		};

		multi-led@248 {
			reg = <248>;
			color = <LED_COLOR_ID_RGB>;
			function = LED_FUNCTION_STATUS;
			function-enumerator = <248>;
		};

		multi-led@249 {
			reg = <249>;
			color = <LED_COLOR_ID_RGB>;
			function = LED_FUNCTION_STATUS;
			function-enumerator = <249>;
		};

		multi-led@250 {
			reg = <250>;
			color = <LED_COLOR_ID_RGB>;
			function = LED_FUNCTION_STATUS;
			function-enumerator = <250>;
		};

		multi-led@251 {
			reg = <251>;
			color = <LED_COLOR_ID_RGB>;
			function = LED_FUNCTION_STATUS;
			function-enumerator = <251>;
		};

		multi-led@252 {
			reg = <252>;
			color = <LED_COLOR_ID_RGB>;
			function = LED_FUNCTION_STATUS;
			function-enumerator = <252>;
		};

		multi-led@253 {
			reg = <253>;
			color = <LED_COLOR_ID_RGB>;
			function = LED_FUNCTION_STATUS;
			function-enumerator = <253>;
		};

		multi-led@254 {
			reg = <254>;
			color = <LED_COLOR_ID_RGB>;
			function = LED_FUNCTION_STATUS;
			function-enumerator = <254>;
		};

		multi-led@255 {
			reg = <255>;
			color = <LED_COLOR_ID_RGB>;
			function = LED_FUNCTION_STATUS;
			function-enumerator = <255>;
		};
	};
};
